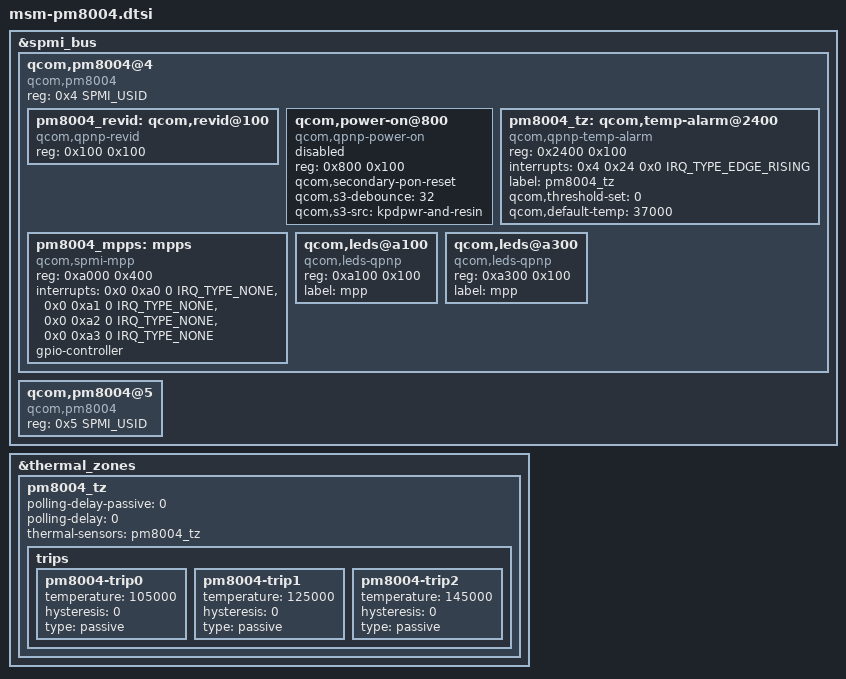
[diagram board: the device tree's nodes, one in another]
/* Copyright (c) 2014-2015, 2019, The Linux Foundation. All rights reserved.
 *
 * This program is free software; you can redistribute it and/or modify
 * it under the terms of the GNU General Public License version 2 and
 * only version 2 as published by the Free Software Foundation.
 *
 * This program is distributed in the hope that it will be useful,
 * but WITHOUT ANY WARRANTY; without even the implied warranty of
 * MERCHANTABILITY or FITNESS FOR A PARTICULAR PURPOSE.  See the
 * GNU General Public License for more details.
 */

#include <dt-bindings/spmi/spmi.h>
#include <dt-bindings/interrupt-controller/irq.h>

&spmi_bus {
	qcom,pm8004@4 {
		compatible = "qcom,pm8004", "qcom,spmi-pmic";
		reg = <0x4 SPMI_USID>;
		#address-cells = <2>;
		#size-cells = <0>;

		pm8004_revid: qcom,revid@100 {
			compatible = "qcom,qpnp-revid";
			reg = <0x100 0x100>;
		};

		qcom,power-on@800 {
			compatible = "qcom,qpnp-power-on";
			reg = <0x800 0x100>;
			qcom,secondary-pon-reset;
			qcom,s3-debounce = <32>;
			qcom,s3-src = "kpdpwr-and-resin";
			status = "disabled";
		};

		pm8004_tz: qcom,temp-alarm@2400 {
			compatible = "qcom,qpnp-temp-alarm";
			reg = <0x2400 0x100>;
			interrupts = <0x4 0x24 0x0 IRQ_TYPE_EDGE_RISING>;
			label = "pm8004_tz";
			qcom,threshold-set = <0>;
			qcom,default-temp = <37000>;
			#thermal-sensor-cells = <0>;
		};

		pm8004_mpps: mpps {
			compatible = "qcom,spmi-mpp";
			reg = <0xa000 0x400>;

			interrupts = <0x0 0xa0 0 IRQ_TYPE_NONE>,
				<0x0 0xa1 0 IRQ_TYPE_NONE>,
				<0x0 0xa2 0 IRQ_TYPE_NONE>,
				<0x0 0xa3 0 IRQ_TYPE_NONE>;
			interrupt-names = "pm8004_mpp1", "pm8004_mpp2",
					"pm8004_mpp3", "pm8004_mpp4";

			gpio-controller;
			#gpio-cells = <2>;
		};

		qcom,leds@a100 {
			compatible = "qcom,leds-qpnp";
			reg = <0xa100 0x100>;
			label = "mpp";
		};

		qcom,leds@a300 {
			compatible = "qcom,leds-qpnp";
			reg = <0xa300 0x100>;
			label = "mpp";
		};
	};

	qcom,pm8004@5 {
		compatible = "qcom,pm8004", "qcom,spmi-pmic";
		reg = <0x5 SPMI_USID>;
		#address-cells = <2>;
		#size-cells = <0>;
	};
};

&thermal_zones {
	pm8004_tz {
		polling-delay-passive = <0>;
		polling-delay = <0>;
		thermal-sensors = <&pm8004_tz>;
		trips {
			pm8004-trip0 {
				temperature = <105000>;
				hysteresis = <0>;
				type = "passive";
			};
			pm8004-trip1 {
				temperature = <125000>;
				hysteresis = <0>;
				type = "passive";
			};
			pm8004-trip2 {
				temperature = <145000>;
				hysteresis = <0>;
				type = "passive";
			};
		};
	};
};
